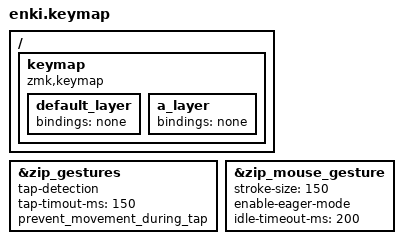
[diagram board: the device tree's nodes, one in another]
#include <behaviors.dtsi>
#include <dt-bindings/zmk/keys.h>
#include <dt-bindings/zmk/input_transform.h>
#include <zephyr/dt-bindings/input/input-event-codes.h>

#include <input/processors.dtsi>
#include <behaviors/input_processor_gestures.dtsi>
#include <behaviors/input_processor_absolute_to_relative.dtsi>
#include <mouse-gesture.dtsi>

/ {
    keymap {
        compatible = "zmk,keymap";

        default_layer {
            bindings = <&none>;
        };
        
        a_layer {
            bindings = <&none>;
        };
    };
};

&zip_gestures {
    tap-detection;
    tap-timout-ms = <150>;
    prevent_movement_during_tap;
};

&zip_mouse_gesture {
    stroke-size = <150>;
    enable-eager-mode;
    idle-timeout-ms = <200>;
};
